# pru_icss_iep register map
Vendor: Texas Instruments
Peripheral module from a debugger description file (folder am335x).
Registers are 32-bit, read-write, no defined reset value unless marked. A register's access mark holds for its fields unless they carry their own. Offsets are as the file gives them; lines under a group give offsets from that group; [hi:lo] are bit positions; {n}, {i} and the like mark numbered series; 'fields as' and 'values as' point back to an identical list; <NAME> marks a mode.

## PRU_ICSS_IEP
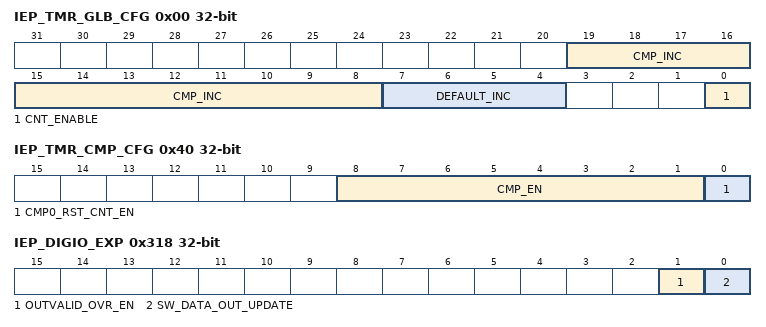
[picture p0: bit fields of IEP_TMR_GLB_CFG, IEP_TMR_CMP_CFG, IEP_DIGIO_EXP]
0x00 IEP_TMR_GLB_CFG access per field — GLOBAL CONFIGURE
  [19:8] CMP_INC rw — Defines the increment value when compensation is active
  [7:4] DEFAULT_INC rw — Defines the default increment value
  [0] CNT_ENABLE rw — Counter enable 0: Disables the counter. The counter maintains the current count. 1: Enables the counter.
0x04 IEP_TMR_GLB_STS access per field — GLOBAL STATUS
  [0] CNT_OVF rw — Counter overflow status. 0: No overflow 1: Overflow occurred
0x08 IEP_TMR_COMPEN access per field — COMPENSATION
  [23:0] COMPEN_CNT rw — Compensation counter. Read returns the current compen_cnt value. 0: Compensation is disabled and counter will increment by DEFAULT_INC. Compensation is enabled until COMPEN_CNT decrements to 0. The COMPEN_CNT value decrements on every iep_clk cycle. When COMPEN_CNT is greater than 0, then count value increments by CMP_INC.
0x0C IEP_TMR_CNT — COUNTER
  [31:0] COUNT — 32-bit count value. Increments by (DEFAULT_INC or CMP_INC) on every positive edge of iep_clk (200MHz).
0x40 IEP_TMR_CMP_CFG access per field — COMPARE CONFIGURE
  [8:1] CMP_EN rw — Compare registers enable, where CMP_EN[0] maps to CMP[0]. 0: Disables event 1: Enables event
  [0] CMP0_RST_CNT_EN rw — Counter reset enable. 0: Disable 1: Enable the reset of the counter if a CMP0 event occurs
0x44 IEP_TMR_CMP_STS access per field — COMPARE STATUS
  [7:0] CMP_HIT rw — Status bit for each of the compare registers, where CMP_HIT[n] maps to CMP[n]. "Match" indicates the current counter is greater than or equal to the compare value. Note it is the firmware's responsibility to handle the IEP overflow. 0: Match has not occurred. 1: Match occurred. The associated hardware event signal will assert and remain high until the status is cleared.
{0x48+4i} IEP_TMR_CMP{i} (i=0..7) — COMPARE{i}
  [31:0] CMP{i} — Compare {i} value
0x300 IEP_DIGIO_CTRL access per field — DIGITAL INPUT OUTPUT CONTROL
  [4] IN_MODE rw — Enable pr1_edio_data_in [31:0] to be sampled by external pr1_edio_latch_in signal. 0: Disable 1: Enable
0x308 IEP_DIGIO_DATA_IN ro — DIGITAL DATA INPUT
  [31:0] DATA_IN — Data input. Sample time of digital inputs is controlled externally by using the pr1_edio_latch_in signal. Must enable by setting DIGIO_CTRL[IN_MODE].
0x30C IEP_DIGIO_DATA_IN_RAW ro — DIGITAL DATA INPUT DIRECT SAMPLE
  [31:0] DATA_IN_RAW — Raw data input. Direct sample of pr1_edio_data_in[31:0].
0x310 IEP_DIGIO_DATA_OUT — DIGITAL DATA OUTPUT
  [31:0] DATA_OUT — Data output, pr1_edio_data_out[31:0].
0x314 IEP_DIGIO_DATA_OUT_EN — DIGITAL DATA OUT ENABLE
  [31:0] DATA_OUT_EN — Enables tri-state control for pr1_edio_data_out[31:0].
0x318 IEP_DIGIO_EXP access per field — DIGIO EXPIRATION CONFIGURE
  [1] OUTVALID_OVR_EN rw — Enable software to control value of pr1_edio_data_out [31:0]. 0: Disable 1: Enable
  [0] SW_DATA_OUT_UPDATE rw — Enable DIGIO_DATA_OUT to be driven out on pr1_edio_data_out. Only valid if OUTVALID_OVR_EN = 1. 0: Disable 1: Enable
